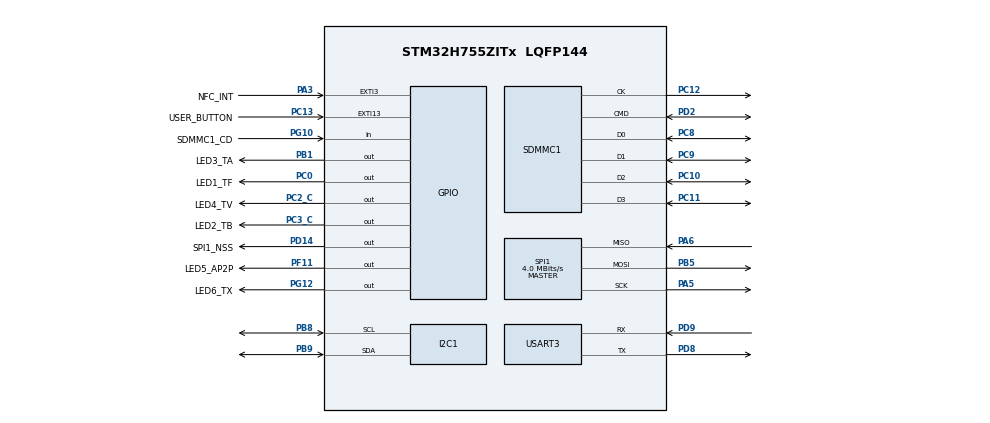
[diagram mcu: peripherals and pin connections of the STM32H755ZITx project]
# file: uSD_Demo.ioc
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CORTEX_M7.default_mode_Activation=1
CortexM4.IPs=BDMA,CORTEX_M4\:I,DMA,FATFS_M4\:I,FREERTOS_M4\:I,GPIO,IWDG2\:I,MDMA,NVIC2\:I,OPENAMP_M4\:I,PDM2PCM_M4\:I,PWR,RCC,RESMGR_UTILITY,SYS_M4\:I,USB_DEVICE_M4\:I,USB_HOST_M4\:I,VREFBUF,WWDG2\:I
CortexM7.IPs=BDMA\:I,CORTEX_M7\:I,DMA\:I,FATFS_M7\:I,FREERTOS_M7\:I,GPIO\:I,IWDG1\:I,MDMA\:I,NVIC1\:I,OPENAMP_M7\:I,PDM2PCM_M7\:I,PWR\:I,RCC\:I,RESMGR_UTILITY\:I,SYS\:I,USB_DEVICE_M7\:I,USB_HOST_M7\:I,VREFBUF\:I,WWDG1\:I,MEMORYMAP\:I,SPI1\:I,I2C1\:I,USART3\:I,SDMMC1\:I
CortexM7.Pins=PC13,PC0,PC2_C,PC3_C,PA3,PB1,PF11,PD14,PG12
FATFS.BSP.number=1
FATFS0.BSP.STBoard=false
FATFS0.BSP.api=Unknown
FATFS0.BSP.instance=PG10
FATFS0.BSP.ip=GPIO
FATFS0.BSP.mode=Input
FATFS0.BSP.name=Detect_SDIO
FATFS0.BSP.solution=PG10
FATFS_M7.USE_DMA_CODE_SD=1
I2C1.Timing=0x00000E14
Mcu.Family=STM32H7
Mcu.Name=STM32H755ZITx
Mcu.Package=LQFP144
NVIC1.EXTI15_10_IRQn=true\:0\:0\:false\:false\:true\:true\:true\:true
NVIC1.EXTI3_IRQn=true\:0\:0\:false\:false\:true\:true\:true\:true
NVIC1.I2C1_EV_IRQn=true\:0\:0\:false\:false\:true\:true\:true\:true
NVIC1.PriorityGroup=NVIC_PRIORITYGROUP_4
NVIC1.SPI1_IRQn=true\:0\:0\:false\:false\:true\:true\:true\:true
NVIC1.USART3_IRQn=true\:0\:0\:false\:false\:true\:true\:true\:true
NVIC2.PriorityGroup=NVIC_PRIORITYGROUP_4
PA3.GPIO_Label=NFC_INT
PA3.PinAttribute=CortexM7
PA3.Signal=GPXTI3
PA5.Mode=Full_Duplex_Master
PA5.PinAttribute=CortexM7
PA5.Signal=SPI1_SCK
PA6.Mode=Full_Duplex_Master
PA6.PinAttribute=CortexM7
PA6.Signal=SPI1_MISO
PB1.GPIO_Label=LED3_TA
PB1.PinAttribute=CortexM7
PB1.Signal=GPIO_Output
PB5.Mode=Full_Duplex_Master
PB5.PinAttribute=CortexM7
PB5.Signal=SPI1_MOSI
PB8.Mode=I2C
PB8.PinAttribute=CortexM7
PB8.Signal=I2C1_SCL
PB9.Mode=I2C
PB9.PinAttribute=CortexM7
PB9.Signal=I2C1_SDA
PC0.GPIO_Label=LED1_TF
PC0.PinAttribute=CortexM7
PC0.Signal=GPIO_Output
PC10.Mode=SD_4_bits_Wide_bus
PC10.PinAttribute=CortexM7
PC10.Signal=SDMMC1_D2
PC11.Mode=SD_4_bits_Wide_bus
PC11.PinAttribute=CortexM7
PC11.Signal=SDMMC1_D3
PC12.Mode=SD_4_bits_Wide_bus
PC12.PinAttribute=CortexM7
PC12.Signal=SDMMC1_CK
PC13.GPIO_Label=USER_BUTTON
PC13.PinAttribute=CortexM7
PC13.Signal=GPXTI13
PC2_C.GPIO_Label=LED4_TV
PC2_C.PinAttribute=CortexM7
PC2_C.Signal=GPIO_Output
PC3_C.GPIO_Label=LED2_TB
PC3_C.PinAttribute=CortexM7
PC3_C.Signal=GPIO_Output
PC8.Mode=SD_4_bits_Wide_bus
PC8.PinAttribute=CortexM7
PC8.Signal=SDMMC1_D0
PC9.Mode=SD_4_bits_Wide_bus
PC9.PinAttribute=CortexM7
PC9.Signal=SDMMC1_D1
PD14.GPIO_Label=SPI1_NSS
PD14.PinAttribute=CortexM7
PD14.Signal=GPIO_Output
PD2.Mode=SD_4_bits_Wide_bus
PD2.PinAttribute=CortexM7
PD2.Signal=SDMMC1_CMD
PD8.Mode=Asynchronous
PD8.PinAttribute=CortexM7
PD8.Signal=USART3_TX
PD9.Mode=Asynchronous
PD9.PinAttribute=CortexM7
PD9.Signal=USART3_RX
PF11.GPIO_Label=LED5_AP2P
PF11.PinAttribute=CortexM7
PF11.Signal=GPIO_Output
PG10.GPIO_Label=SDMMC1_CD
PG10.Signal=GPIO_Input
PG12.GPIO_Label=LED6_TX
PG12.PinAttribute=CortexM7
PG12.Signal=GPIO_Output
ProjectManager.HeapSize=M4-0x200,M7-0x200
ProjectManager.StackSize=M4-0x400,M7-0x400
ProjectManager.TargetToolchain=STM32CubeIDE
RCC.ADCFreq_Value=96000000
RCC.APB1Freq_Value=64000000
RCC.APB2Freq_Value=64000000
RCC.APB3Freq_Value=64000000
RCC.APB4Freq_Value=64000000
RCC.CortexFreq_Value=64000000
RCC.DIVN2=96
RCC.HCLKFreq_Value=64000000
RCC.I2C123CLockSelection=RCC_I2C123CLKSOURCE_CSI
RCC.PLL1_VCO_SEL-AdvancedSettings=RCC_PLL1VCOWIDE
RCC.SDMMC1CLockSelection=RCC_SDMMCCLKSOURCE_PLL2
RCC.SPI123CLockSelection=RCC_SPI123CLKSOURCE_CLKP
RCC.SYSCLKFreq_VALUE=64000000
RCC.USART234578CLockSelection=RCC_USART234578CLKSOURCE_CSI
RCC.USBFreq_Value=129000000
SPI1.BaudRatePrescaler=SPI_BAUDRATEPRESCALER_16
SPI1.CLKPhase=SPI_PHASE_2EDGE
SPI1.CalculateBaudRate=4.0 MBits/s
SPI1.DataSize=SPI_DATASIZE_8BIT
SPI1.Direction=SPI_DIRECTION_2LINES
SPI1.Mode=SPI_MODE_MASTER
SPI1.VirtualType=VM_MASTER
SYS.userName=SYS_M7
USART3.VirtualMode-Asynchronous=VM_ASYNC
VP_FATFS_M7_VS_SDIO.Mode=SDIO
VP_MEMORYMAP_VS_MEMORYMAP.Mode=CurAppReg
VP_SYS_M4_VS_Systick.Mode=SysTick
board=custom

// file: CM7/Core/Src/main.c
/* USER CODE BEGIN Header */
/**
  ******************************************************************************
  * @file           : main.c
  * @brief          : Main program body
  ******************************************************************************
  * @attention
  *
  * Copyright (c) 2025 STMicroelectronics.
  * All rights reserved.
  *
  * This software is licensed under terms that can be found in the LICENSE file
  * in the root directory of this software component.
  * If no LICENSE file comes with this software, it is provided AS-IS.
  *
  ******************************************************************************
  */
/* USER CODE END Header */
#include "main.h"
#include "fatfs.h"

/* USER CODE BEGIN Includes */
#include "stdio.h"
/* USER CODE END Includes */

/* USER CODE BEGIN PD */

#ifndef HSEM_ID_0
#define HSEM_ID_0 (0U) /* HW semaphore 0*/
#endif

/* USER CODE END PD */

I2C_HandleTypeDef hi2c1;

SD_HandleTypeDef hsd1;

SPI_HandleTypeDef hspi1;

UART_HandleTypeDef huart3;

/* USER CODE BEGIN PV */
FATFS fatfs;
FIL fil;
FRESULT fres;

char demoText[] = "Test\nTest2";
UINT bytesToWrite = 0;
UINT bytesWritten = 0;

/* USER CODE END PV */

void SystemClock_Config(void);
void PeriphCommonClock_Config(void);
static void MPU_Config(void);
static void MX_GPIO_Init(void);
static void MX_I2C1_Init(void);
static void MX_SPI1_Init(void);
static void MX_SDMMC1_SD_Init(void);
static void MX_USART3_UART_Init(void);

int main(void)
{

/* USER CODE BEGIN Boot_Mode_Sequence_0 */
  int32_t timeout;
/* USER CODE END Boot_Mode_Sequence_0 */

  /* MPU Configuration--------------------------------------------------------*/
  MPU_Config();

/* USER CODE BEGIN Boot_Mode_Sequence_1 */
  /* Wait until CPU2 boots and enters in stop mode or timeout*/
  timeout = 0xFFFF;
  while((__HAL_RCC_GET_FLAG(RCC_FLAG_D2CKRDY) != RESET) && (timeout-- > 0));
  if ( timeout < 0 )
  {
  Error_Handler();
  }
/* USER CODE END Boot_Mode_Sequence_1 */
  /* MCU Configuration--------------------------------------------------------*/

  /* Reset of all peripherals, Initializes the Flash interface and the Systick. */
  HAL_Init();

  /* Configure the system clock */
  SystemClock_Config();

  /* Configure the peripherals common clocks */
  PeriphCommonClock_Config();
/* USER CODE BEGIN Boot_Mode_Sequence_2 */
/* When system initialization is finished, Cortex-M7 will release Cortex-M4 by means of
HSEM notification */
/*HW semaphore Clock enable*/
__HAL_RCC_HSEM_CLK_ENABLE();
/*Take HSEM */
HAL_HSEM_FastTake(HSEM_ID_0);
/*Release HSEM in order to notify the CPU2(CM4)*/
HAL_HSEM_Release(HSEM_ID_0,0);
/* wait until CPU2 wakes up from stop mode */
timeout = 0xFFFF;
while((__HAL_RCC_GET_FLAG(RCC_FLAG_D2CKRDY) == RESET) && (timeout-- > 0));
if ( timeout < 0 )
{
Error_Handler();
}
/* USER CODE END Boot_Mode_Sequence_2 */

  /* Initialize all configured peripherals */
  MX_GPIO_Init();
  MX_I2C1_Init();
  MX_SPI1_Init();
  MX_SDMMC1_SD_Init();
  MX_USART3_UART_Init();
  MX_FATFS_Init();
  /* USER CODE BEGIN 2 */

  fres = f_mount(&fatfs, "", 1);
  if (fres != FR_OK) printf("f_mount error (%i)\r\n", fres);

  fres = f_open(&fil, "test.txt", FA_OPEN_ALWAYS | FA_WRITE); //open and read/write access, if does not exist create new
  if (fres != FR_OK) printf("f_open error (%i)\r\n", fres);

  fres = f_write(&fil, &demoText, sizeof(demoText), &bytesWritten);
  if (fres != FR_OK) printf("f_open error (%i)\r\n", fres);

  /* USER CODE END 2 */

  /* Infinite loop */
  while (1)
  {

  }
}

void SystemClock_Config(void)
{
  RCC_OscInitTypeDef RCC_OscInitStruct = {0};
  RCC_ClkInitTypeDef RCC_ClkInitStruct = {0};

  /** Supply configuration update enable
  */
  HAL_PWREx_ConfigSupply(PWR_DIRECT_SMPS_SUPPLY);

  /** Configure the main internal regulator output voltage
  */
  __HAL_PWR_VOLTAGESCALING_CONFIG(PWR_REGULATOR_VOLTAGE_SCALE3);

  while(!__HAL_PWR_GET_FLAG(PWR_FLAG_VOSRDY)) {}

  /** Macro to configure the PLL clock source
  */
  __HAL_RCC_PLL_PLLSOURCE_CONFIG(RCC_PLLSOURCE_HSI);

  /** Initializes the RCC Oscillators according to the specified parameters
  * in the RCC_OscInitTypeDef structure.
  */
  RCC_OscInitStruct.OscillatorType = RCC_OSCILLATORTYPE_CSI|RCC_OSCILLATORTYPE_HSI;
  RCC_OscInitStruct.HSIState = RCC_HSI_DIV1;
  RCC_OscInitStruct.HSICalibrationValue = RCC_HSICALIBRATION_DEFAULT;
  RCC_OscInitStruct.CSIState = RCC_CSI_ON;
  RCC_OscInitStruct.CSICalibrationValue = RCC_CSICALIBRATION_DEFAULT;
  RCC_OscInitStruct.PLL.PLLState = RCC_PLL_NONE;
  if (HAL_RCC_OscConfig(&RCC_OscInitStruct) != HAL_OK)
  {
    Error_Handler();
  }

  /** Initializes the CPU, AHB and APB buses clocks
  */
  RCC_ClkInitStruct.ClockType = RCC_CLOCKTYPE_HCLK|RCC_CLOCKTYPE_SYSCLK
                              |RCC_CLOCKTYPE_PCLK1|RCC_CLOCKTYPE_PCLK2
                              |RCC_CLOCKTYPE_D3PCLK1|RCC_CLOCKTYPE_D1PCLK1;
  RCC_ClkInitStruct.SYSCLKSource = RCC_SYSCLKSOURCE_HSI;
  RCC_ClkInitStruct.SYSCLKDivider = RCC_SYSCLK_DIV1;
  RCC_ClkInitStruct.AHBCLKDivider = RCC_HCLK_DIV1;
  RCC_ClkInitStruct.APB3CLKDivider = RCC_APB3_DIV1;
  RCC_ClkInitStruct.APB1CLKDivider = RCC_APB1_DIV1;
  RCC_ClkInitStruct.APB2CLKDivider = RCC_APB2_DIV1;
  RCC_ClkInitStruct.APB4CLKDivider = RCC_APB4_DIV1;

  if (HAL_RCC_ClockConfig(&RCC_ClkInitStruct, FLASH_LATENCY_1) != HAL_OK)
  {
    Error_Handler();
  }
}

void PeriphCommonClock_Config(void)
{
  RCC_PeriphCLKInitTypeDef PeriphClkInitStruct = {0};

  /** Initializes the peripherals clock
  */
  PeriphClkInitStruct.PeriphClockSelection = RCC_PERIPHCLK_CKPER;
  PeriphClkInitStruct.CkperClockSelection = RCC_CLKPSOURCE_HSI;
  if (HAL_RCCEx_PeriphCLKConfig(&PeriphClkInitStruct) != HAL_OK)
  {
    Error_Handler();
  }
}

static void MX_I2C1_Init(void)
{

  hi2c1.Instance = I2C1;
  hi2c1.Init.Timing = 0x00000E14;
  hi2c1.Init.OwnAddress1 = 0;
  hi2c1.Init.AddressingMode = I2C_ADDRESSINGMODE_7BIT;
  hi2c1.Init.DualAddressMode = I2C_DUALADDRESS_DISABLE;
  hi2c1.Init.OwnAddress2 = 0;
  hi2c1.Init.OwnAddress2Masks = I2C_OA2_NOMASK;
  hi2c1.Init.GeneralCallMode = I2C_GENERALCALL_DISABLE;
  hi2c1.Init.NoStretchMode = I2C_NOSTRETCH_DISABLE;
  if (HAL_I2C_Init(&hi2c1) != HAL_OK)
  {
    Error_Handler();
  }

  /** Configure Analogue filter
  */
  if (HAL_I2CEx_ConfigAnalogFilter(&hi2c1, I2C_ANALOGFILTER_ENABLE) != HAL_OK)
  {
    Error_Handler();
  }

  /** Configure Digital filter
  */
  if (HAL_I2CEx_ConfigDigitalFilter(&hi2c1, 0) != HAL_OK)
  {
    Error_Handler();
  }

}

static void MX_SDMMC1_SD_Init(void)
{

  hsd1.Instance = SDMMC1;
  hsd1.Init.ClockEdge = SDMMC_CLOCK_EDGE_RISING;
  hsd1.Init.ClockPowerSave = SDMMC_CLOCK_POWER_SAVE_DISABLE;
  hsd1.Init.BusWide = SDMMC_BUS_WIDE_4B;
  hsd1.Init.HardwareFlowControl = SDMMC_HARDWARE_FLOW_CONTROL_DISABLE;
  hsd1.Init.ClockDiv = 0;
  if (HAL_SD_Init(&hsd1) != HAL_OK)
  {
    Error_Handler();
  }

}

static void MX_SPI1_Init(void)
{

  /* SPI1 parameter configuration*/
  hspi1.Instance = SPI1;
  hspi1.Init.Mode = SPI_MODE_MASTER;
  hspi1.Init.Direction = SPI_DIRECTION_2LINES;
  hspi1.Init.DataSize = SPI_DATASIZE_8BIT;
  hspi1.Init.CLKPolarity = SPI_POLARITY_LOW;
  hspi1.Init.CLKPhase = SPI_PHASE_2EDGE;
  hspi1.Init.NSS = SPI_NSS_SOFT;
  hspi1.Init.BaudRatePrescaler = SPI_BAUDRATEPRESCALER_16;
  hspi1.Init.FirstBit = SPI_FIRSTBIT_MSB;
  hspi1.Init.TIMode = SPI_TIMODE_DISABLE;
  hspi1.Init.CRCCalculation = SPI_CRCCALCULATION_DISABLE;
  hspi1.Init.CRCPolynomial = 0x0;
  hspi1.Init.NSSPMode = SPI_NSS_PULSE_ENABLE;
  hspi1.Init.NSSPolarity = SPI_NSS_POLARITY_LOW;
  hspi1.Init.FifoThreshold = SPI_FIFO_THRESHOLD_01DATA;
  hspi1.Init.TxCRCInitializationPattern = SPI_CRC_INITIALIZATION_ALL_ZERO_PATTERN;
  hspi1.Init.RxCRCInitializationPattern = SPI_CRC_INITIALIZATION_ALL_ZERO_PATTERN;
  hspi1.Init.MasterSSIdleness = SPI_MASTER_SS_IDLENESS_00CYCLE;
  hspi1.Init.MasterInterDataIdleness = SPI_MASTER_INTERDATA_IDLENESS_00CYCLE;
  hspi1.Init.MasterReceiverAutoSusp = SPI_MASTER_RX_AUTOSUSP_DISABLE;
  hspi1.Init.MasterKeepIOState = SPI_MASTER_KEEP_IO_STATE_DISABLE;
  hspi1.Init.IOSwap = SPI_IO_SWAP_DISABLE;
  if (HAL_SPI_Init(&hspi1) != HAL_OK)
  {
    Error_Handler();
  }

}

static void MX_USART3_UART_Init(void)
{

  huart3.Instance = USART3;
  huart3.Init.BaudRate = 115200;
  huart3.Init.WordLength = UART_WORDLENGTH_8B;
  huart3.Init.StopBits = UART_STOPBITS_1;
  huart3.Init.Parity = UART_PARITY_NONE;
  huart3.Init.Mode = UART_MODE_TX_RX;
  huart3.Init.HwFlowCtl = UART_HWCONTROL_NONE;
  huart3.Init.OverSampling = UART_OVERSAMPLING_16;
  huart3.Init.OneBitSampling = UART_ONE_BIT_SAMPLE_DISABLE;
  huart3.Init.ClockPrescaler = UART_PRESCALER_DIV1;
  huart3.AdvancedInit.AdvFeatureInit = UART_ADVFEATURE_NO_INIT;
  if (HAL_UART_Init(&huart3) != HAL_OK)
  {
    Error_Handler();
  }
  if (HAL_UARTEx_SetTxFifoThreshold(&huart3, UART_TXFIFO_THRESHOLD_1_8) != HAL_OK)
  {
    Error_Handler();
  }
  if (HAL_UARTEx_SetRxFifoThreshold(&huart3, UART_RXFIFO_THRESHOLD_1_8) != HAL_OK)
  {
    Error_Handler();
  }
  if (HAL_UARTEx_DisableFifoMode(&huart3) != HAL_OK)
  {
    Error_Handler();
  }

}

static void MX_GPIO_Init(void)
{
  GPIO_InitTypeDef GPIO_InitStruct = {0};

  /* GPIO Ports Clock Enable */
  __HAL_RCC_GPIOC_CLK_ENABLE();
  __HAL_RCC_GPIOA_CLK_ENABLE();
  __HAL_RCC_GPIOB_CLK_ENABLE();
  __HAL_RCC_GPIOF_CLK_ENABLE();
  __HAL_RCC_GPIOD_CLK_ENABLE();
  __HAL_RCC_GPIOG_CLK_ENABLE();

  /*Configure GPIO pin Output Level */
  HAL_GPIO_WritePin(GPIOC, LED1_TF_Pin|LED4_TV_Pin|LED2_TB_Pin, GPIO_PIN_RESET);

  /*Configure GPIO pin Output Level */
  HAL_GPIO_WritePin(LED3_TA_GPIO_Port, LED3_TA_Pin, GPIO_PIN_RESET);

  /*Configure GPIO pin Output Level */
  HAL_GPIO_WritePin(LED5_AP2P_GPIO_Port, LED5_AP2P_Pin, GPIO_PIN_RESET);

  /*Configure GPIO pin Output Level */
  HAL_GPIO_WritePin(SPI1_NSS_GPIO_Port, SPI1_NSS_Pin, GPIO_PIN_RESET);

  /*Configure GPIO pin Output Level */
  HAL_GPIO_WritePin(LED6_TX_GPIO_Port, LED6_TX_Pin, GPIO_PIN_RESET);

  /*Configure GPIO pin : USER_BUTTON_Pin */
  GPIO_InitStruct.Pin = USER_BUTTON_Pin;
  GPIO_InitStruct.Mode = GPIO_MODE_IT_RISING;
  GPIO_InitStruct.Pull = GPIO_NOPULL;
  HAL_GPIO_Init(USER_BUTTON_GPIO_Port, &GPIO_InitStruct);

  /*Configure GPIO pins : LED1_TF_Pin LED4_TV_Pin LED2_TB_Pin */
  GPIO_InitStruct.Pin = LED1_TF_Pin|LED4_TV_Pin|LED2_TB_Pin;
  GPIO_InitStruct.Mode = GPIO_MODE_OUTPUT_PP;
  GPIO_InitStruct.Pull = GPIO_NOPULL;
  GPIO_InitStruct.Speed = GPIO_SPEED_FREQ_LOW;
  HAL_GPIO_Init(GPIOC, &GPIO_InitStruct);

  /*Configure GPIO pin : NFC_INT_Pin */
  GPIO_InitStruct.Pin = NFC_INT_Pin;
  GPIO_InitStruct.Mode = GPIO_MODE_IT_RISING;
  GPIO_InitStruct.Pull = GPIO_NOPULL;
  HAL_GPIO_Init(NFC_INT_GPIO_Port, &GPIO_InitStruct);

  /*Configure GPIO pin : LED3_TA_Pin */
  GPIO_InitStruct.Pin = LED3_TA_Pin;
  GPIO_InitStruct.Mode = GPIO_MODE_OUTPUT_PP;
  GPIO_InitStruct.Pull = GPIO_NOPULL;
  GPIO_InitStruct.Speed = GPIO_SPEED_FREQ_LOW;
  HAL_GPIO_Init(LED3_TA_GPIO_Port, &GPIO_InitStruct);

  /*Configure GPIO pin : LED5_AP2P_Pin */
  GPIO_InitStruct.Pin = LED5_AP2P_Pin;
  GPIO_InitStruct.Mode = GPIO_MODE_OUTPUT_PP;
  GPIO_InitStruct.Pull = GPIO_NOPULL;
  GPIO_InitStruct.Speed = GPIO_SPEED_FREQ_LOW;
  HAL_GPIO_Init(LED5_AP2P_GPIO_Port, &GPIO_InitStruct);

  /*Configure GPIO pin : SPI1_NSS_Pin */
  GPIO_InitStruct.Pin = SPI1_NSS_Pin;
  GPIO_InitStruct.Mode = GPIO_MODE_OUTPUT_PP;
  GPIO_InitStruct.Pull = GPIO_NOPULL;
  GPIO_InitStruct.Speed = GPIO_SPEED_FREQ_LOW;
  HAL_GPIO_Init(SPI1_NSS_GPIO_Port, &GPIO_InitStruct);

  /*Configure GPIO pin : SDMMC1_CD_Pin */
  GPIO_InitStruct.Pin = SDMMC1_CD_Pin;
  GPIO_InitStruct.Mode = GPIO_MODE_INPUT;
  GPIO_InitStruct.Pull = GPIO_NOPULL;
  HAL_GPIO_Init(SDMMC1_CD_GPIO_Port, &GPIO_InitStruct);

  /*Configure GPIO pin : LED6_TX_Pin */
  GPIO_InitStruct.Pin = LED6_TX_Pin;
  GPIO_InitStruct.Mode = GPIO_MODE_OUTPUT_PP;
  GPIO_InitStruct.Pull = GPIO_NOPULL;
  GPIO_InitStruct.Speed = GPIO_SPEED_FREQ_LOW;
  HAL_GPIO_Init(LED6_TX_GPIO_Port, &GPIO_InitStruct);

  /* EXTI interrupt init*/
  HAL_NVIC_SetPriority(NFC_INT_EXTI_IRQn, 0, 0);
  HAL_NVIC_EnableIRQ(NFC_INT_EXTI_IRQn);

  HAL_NVIC_SetPriority(USER_BUTTON_EXTI_IRQn, 0, 0);
  HAL_NVIC_EnableIRQ(USER_BUTTON_EXTI_IRQn);

}

 /* MPU Configuration */

void MPU_Config(void)
{
  MPU_Region_InitTypeDef MPU_InitStruct = {0};

  /* Disables the MPU */
  HAL_MPU_Disable();

  /** Initializes and configures the Region and the memory to be protected
  */
  MPU_InitStruct.Enable = MPU_REGION_ENABLE;
  MPU_InitStruct.Number = MPU_REGION_NUMBER0;
  MPU_InitStruct.BaseAddress = 0x0;
  MPU_InitStruct.Size = MPU_REGION_SIZE_4GB;
  MPU_InitStruct.SubRegionDisable = 0x87;
  MPU_InitStruct.TypeExtField = MPU_TEX_LEVEL0;
  MPU_InitStruct.AccessPermission = MPU_REGION_NO_ACCESS;
  MPU_InitStruct.DisableExec = MPU_INSTRUCTION_ACCESS_DISABLE;
  MPU_InitStruct.IsShareable = MPU_ACCESS_SHAREABLE;
  MPU_InitStruct.IsCacheable = MPU_ACCESS_NOT_CACHEABLE;
  MPU_InitStruct.IsBufferable = MPU_ACCESS_NOT_BUFFERABLE;

  HAL_MPU_ConfigRegion(&MPU_InitStruct);
  /* Enables the MPU */
  HAL_MPU_Enable(MPU_PRIVILEGED_DEFAULT);

}

void Error_Handler(void)
{
  __disable_irq();
  while (1)
  {
  }
}
